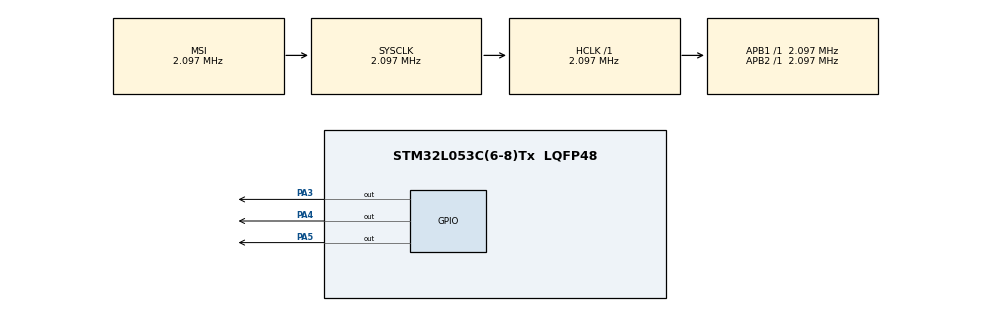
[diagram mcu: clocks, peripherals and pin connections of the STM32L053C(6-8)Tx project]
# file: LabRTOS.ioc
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FREERTOS.Tasks01=defaultTask,0,128,StartDefaultTask,Default,NULL
FREERTOS.configTOTAL_HEAP_SIZE=5000
Mcu.Family=STM32L0
Mcu.Name=STM32L053C(6-8)Tx
Mcu.Package=LQFP48
NVIC.TIM22_IRQn=true\:0\:0\:false\:false\:true\:false\:false
NVIC.TimeBase=TIM22_IRQn
NVIC.TimeBaseIP=TIM22
PA3.Signal=GPIO_Output
PA4.Signal=GPIO_Output
PA5.Signal=GPIO_Output
ProjectManager.HeapSize=0x200
ProjectManager.StackSize=0x400
ProjectManager.TargetToolchain=TrueSTUDIO
RCC.AHBFreq_Value=2097000
RCC.APB1Freq_Value=2097000
RCC.APB1TimFreq_Value=2097000
RCC.APB2Freq_Value=2097000
RCC.APB2TimFreq_Value=2097000
RCC.HSE_VALUE=8000000
RCC.HSI16_VALUE=16000000
RCC.HSI48_VALUE=48000000
RCC.HSI_VALUE=16000000
RCC.LSE_VALUE=32768
RCC.MSI_VALUE=2097000
RCC.SYSCLKFreq_VALUE=2097000
RCC.VCOOutputFreq_Value=48000000
VP_FREERTOS_VS_ENABLE.Mode=Enabled
VP_SYS_VS_tim22.Mode=TIM22
board=custom

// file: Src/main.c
/**
  ******************************************************************************
  * @file           : main.c
  * @brief          : Main program body
  ******************************************************************************
  * This notice applies to any and all portions of this file
  * that are not between comment pairs USER CODE BEGIN and
  * USER CODE END. Other portions of this file, whether
  * inserted by the user or by software development tools
  * are owned by their respective copyright owners.
  *
  * Copyright (c) 2018 STMicroelectronics International N.V.
  * All rights reserved.
  *
  * Redistribution and use in source and binary forms, with or without
  * modification, are permitted, provided that the following conditions are met:
  *
  * 1. Redistribution of source code must retain the above copyright notice,
  *    this list of conditions and the following disclaimer.
  * 2. Redistributions in binary form must reproduce the above copyright notice,
  *    this list of conditions and the following disclaimer in the documentation
  *    and/or other materials provided with the distribution.
  * 3. Neither the name of STMicroelectronics nor the names of other
  *    contributors to this software may be used to endorse or promote products
  *    derived from this software without specific written permission.
  * 4. This software, including modifications and/or derivative works of this
  *    software, must execute solely and exclusively on microcontroller or
  *    microprocessor devices manufactured by or for STMicroelectronics.
  * 5. Redistribution and use of this software other than as permitted under
  *    this license is void and will automatically terminate your rights under
  *    this license.
  *
  * THIS SOFTWARE IS PROVIDED BY STMICROELECTRONICS AND CONTRIBUTORS "AS IS"
  * AND ANY EXPRESS, IMPLIED OR STATUTORY WARRANTIES, INCLUDING, BUT NOT
  * LIMITED TO, THE IMPLIED WARRANTIES OF MERCHANTABILITY, FITNESS FOR A
  * PARTICULAR PURPOSE AND NON-INFRINGEMENT OF THIRD PARTY INTELLECTUAL PROPERTY
  * RIGHTS ARE DISCLAIMED TO THE FULLEST EXTENT PERMITTED BY LAW. IN NO EVENT
  * SHALL STMICROELECTRONICS OR CONTRIBUTORS BE LIABLE FOR ANY DIRECT, INDIRECT,
  * INCIDENTAL, SPECIAL, EXEMPLARY, OR CONSEQUENTIAL DAMAGES (INCLUDING, BUT NOT
  * LIMITED TO, PROCUREMENT OF SUBSTITUTE GOODS OR SERVICES; LOSS OF USE, DATA,
  * OR PROFITS; OR BUSINESS INTERRUPTION) HOWEVER CAUSED AND ON ANY THEORY OF
  * LIABILITY, WHETHER IN CONTRACT, STRICT LIABILITY, OR TORT (INCLUDING
  * NEGLIGENCE OR OTHERWISE) ARISING IN ANY WAY OUT OF THE USE OF THIS SOFTWARE,
  * EVEN IF ADVISED OF THE POSSIBILITY OF SUCH DAMAGE.
  *
  ******************************************************************************
  */
#include "main.h"
#include "stm32l0xx_hal.h"
#include "cmsis_os.h"

osThreadId defaultTaskHandle;

/* USER CODE BEGIN PV */
/* Private variables ---------------------------------------------------------*/
SemaphoreHandle_t xLedSemaphore;

/* USER CODE END PV */

void SystemClock_Config(void);
static void MX_GPIO_Init(void);
void StartDefaultTask(void const * argument);

/* USER CODE BEGIN PFP */
/* Private function prototypes -----------------------------------------------*/
void StartTask_1(void const * argument);
void StartTask_2(void const * argument);
void StartTask_3(void const * argument);
/* USER CODE END PFP */

int main(void)
{

  /* MCU Configuration----------------------------------------------------------*/

  /* Reset of all peripherals, Initializes the Flash interface and the Systick. */
  HAL_Init();

  /* Configure the system clock */
  SystemClock_Config();

  /* Initialize all configured peripherals */
  MX_GPIO_Init();

  /* USER CODE BEGIN RTOS_SEMAPHORES */
  /* add semaphores, ... */
  xLedSemaphore = xSemaphoreCreateMutex();
  if(xLedSemaphore == NULL){
	  for(;;){
		  osDelay(10);
		  //NO semophore was made
	  }
  }
  /* USER CODE END RTOS_SEMAPHORES */

  /* Create the thread(s) */
  /* definition and creation of defaultTask */
  osThreadDef(defaultTask, StartDefaultTask, osPriorityNormal, 0, 128);
  defaultTaskHandle = osThreadCreate(osThread(defaultTask), NULL);

  /* USER CODE BEGIN RTOS_THREADS */
  /* add threads, ... */
  TaskHandle_t Task_1 = NULL;
  xTaskCreate(StartTask_1, "Task1", configMINIMAL_STACK_SIZE, NULL, 2, &Task_1 );

  TaskHandle_t Task_2 = NULL;
  xTaskCreate(StartTask_2, "Task2", configMINIMAL_STACK_SIZE, NULL, 2, &Task_2 );

  TaskHandle_t Task_3 = NULL;
  xTaskCreate(StartTask_3, "Task3", configMINIMAL_STACK_SIZE, NULL, 2, &Task_3 );
  /* USER CODE END RTOS_THREADS */

  /* Start scheduler */
  osKernelStart();

  /* We should never get here as control is now taken by the scheduler */

  /* Infinite loop */
  while(1)
  {
	  osDelay(1);

  }

}

void SystemClock_Config(void)
{

  RCC_OscInitTypeDef RCC_OscInitStruct;
  RCC_ClkInitTypeDef RCC_ClkInitStruct;

    /**Configure the main internal regulator output voltage
    */
  __HAL_PWR_VOLTAGESCALING_CONFIG(PWR_REGULATOR_VOLTAGE_SCALE1);

    /**Initializes the CPU, AHB and APB busses clocks
    */
  RCC_OscInitStruct.OscillatorType = RCC_OSCILLATORTYPE_MSI;
  RCC_OscInitStruct.MSIState = RCC_MSI_ON;
  RCC_OscInitStruct.MSICalibrationValue = 0;
  RCC_OscInitStruct.MSIClockRange = RCC_MSIRANGE_5;
  RCC_OscInitStruct.PLL.PLLState = RCC_PLL_NONE;
  if (HAL_RCC_OscConfig(&RCC_OscInitStruct) != HAL_OK)
  {
    _Error_Handler(__FILE__, __LINE__);
  }

    /**Initializes the CPU, AHB and APB busses clocks
    */
  RCC_ClkInitStruct.ClockType = RCC_CLOCKTYPE_HCLK|RCC_CLOCKTYPE_SYSCLK
                              |RCC_CLOCKTYPE_PCLK1|RCC_CLOCKTYPE_PCLK2;
  RCC_ClkInitStruct.SYSCLKSource = RCC_SYSCLKSOURCE_MSI;
  RCC_ClkInitStruct.AHBCLKDivider = RCC_SYSCLK_DIV1;
  RCC_ClkInitStruct.APB1CLKDivider = RCC_HCLK_DIV1;
  RCC_ClkInitStruct.APB2CLKDivider = RCC_HCLK_DIV1;

  if (HAL_RCC_ClockConfig(&RCC_ClkInitStruct, FLASH_LATENCY_0) != HAL_OK)
  {
    _Error_Handler(__FILE__, __LINE__);
  }

    /**Configure the Systick interrupt time
    */
  HAL_SYSTICK_Config(HAL_RCC_GetHCLKFreq()/1000);

    /**Configure the Systick
    */
  HAL_SYSTICK_CLKSourceConfig(SYSTICK_CLKSOURCE_HCLK);

  /* SysTick_IRQn interrupt configuration */
  HAL_NVIC_SetPriority(SysTick_IRQn, 3, 0);
}

/** Configure pins as
        * Analog
        * Input
        * Output
        * EVENT_OUT
        * EXTI
*/
static void MX_GPIO_Init(void)
{

  GPIO_InitTypeDef GPIO_InitStruct;

  /* GPIO Ports Clock Enable */
  __HAL_RCC_GPIOA_CLK_ENABLE();

  /*Configure GPIO pin Output Level */
  HAL_GPIO_WritePin(GPIOA, GPIO_PIN_3|GPIO_PIN_4|GPIO_PIN_5, GPIO_PIN_RESET);

  /*Configure GPIO pins : PA3 PA4 PA5 */
  GPIO_InitStruct.Pin = GPIO_PIN_3|GPIO_PIN_4|GPIO_PIN_5;
  GPIO_InitStruct.Mode = GPIO_MODE_OUTPUT_PP;
  GPIO_InitStruct.Pull = GPIO_NOPULL;
  GPIO_InitStruct.Speed = GPIO_SPEED_FREQ_LOW;
  HAL_GPIO_Init(GPIOA, &GPIO_InitStruct);

}

/* USER CODE BEGIN 4 */
void blick_led(uint16_t pin){
	/* See if we can obtain the semaphore.  If the semaphore is not
	available wait 10 ticks to see if it becomes free. */
	if( xSemaphoreTake( xLedSemaphore, ( TickType_t ) 0 ) == pdTRUE )
	{
		/* We were able to obtain the semaphore and can now access the
		shared resource. */

		HAL_GPIO_TogglePin(GPIOA,pin);

		/* We have finished accessing the shared resource.  Release the
		semaphore. */
		if( xSemaphoreGive( xLedSemaphore ) != pdTRUE )
		{
			for(;;){
				//osDelay(10);
			}
			// We would not expect this call to fail because we must have
			// obtained the semaphore to get here.
		}
	}
	else
	{

		/* We could not obtain the semaphore and can therefore not access
		the shared resource safely. */
		//HAL_GPIO_TogglePin(GPIOA,GPIO_PIN_3);
		//HAL_Delay(100);
	}
}

void StartTask_1(void const * argument)
{

  /* Infinite loop */
  for(;;)
  {
	  blick_led(GPIO_PIN_5);
	  vTaskDelay(20);
  }
}

void StartTask_2(void const * argument)
{
  /* Infinite loop */
  for(;;)
  {
	  blick_led(GPIO_PIN_4);
	  vTaskDelay(20);
  }
}

void StartTask_3(void const * argument)
{
  /* Infinite loop */
  for(;;)
  {
	  blick_led(GPIO_PIN_3);
	  vTaskDelay(20);
  }
}

/* USER CODE END 4 */

void StartDefaultTask(void const * argument)
{

  for(;;)
  {
	  osDelay(1);
  }
}

void HAL_TIM_PeriodElapsedCallback(TIM_HandleTypeDef *htim)
{
  if (htim->Instance == TIM22) {
    HAL_IncTick();
  }
}

void _Error_Handler(char *file, int line)
{
  while(1)
  {
  }
}

/************************ (C) COPYRIGHT STMicroelectronics *****END OF FILE****/
